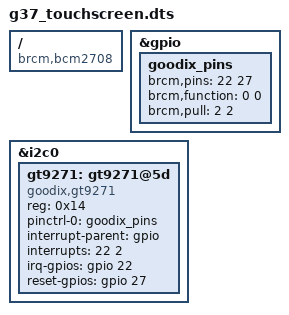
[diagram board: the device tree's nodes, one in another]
// Device tree overlay for I2C connected Goodix gt9271 multiple touch controller
// Acme Systems version for 7 inch DPI display
/dts-v1/;
/plugin/;

/ {
        compatible = "brcm,bcm2708";

        fragment@0 {
                target = <&gpio>;
                __overlay__ {
                        goodix_pins: goodix_pins {
                                brcm,pins = <22 27>; // interrupt and reset
                                brcm,function = <0 0>; // in
                                brcm,pull = <2 2>; // pull-up
                        };
                };
        };

        fragment@1 {
                target = <&i2c0>;
                __overlay__ {
                        #address-cells = <1>;
                        #size-cells = <0>;
                        status = "okay";

                        gt9271: gt9271@5d {
                                compatible = "goodix,gt9271";
                                reg = <0x14>;
                                pinctrl-names = "default";
                                pinctrl-0 = <&goodix_pins>;
                                interrupt-parent = <&gpio>;
                                interrupts = <22 2>; // high-to-low edge triggered
                                irq-gpios = <&gpio 22 0>;
                                reset-gpios = <&gpio 27 0>;
                        };
                };
        };
};
